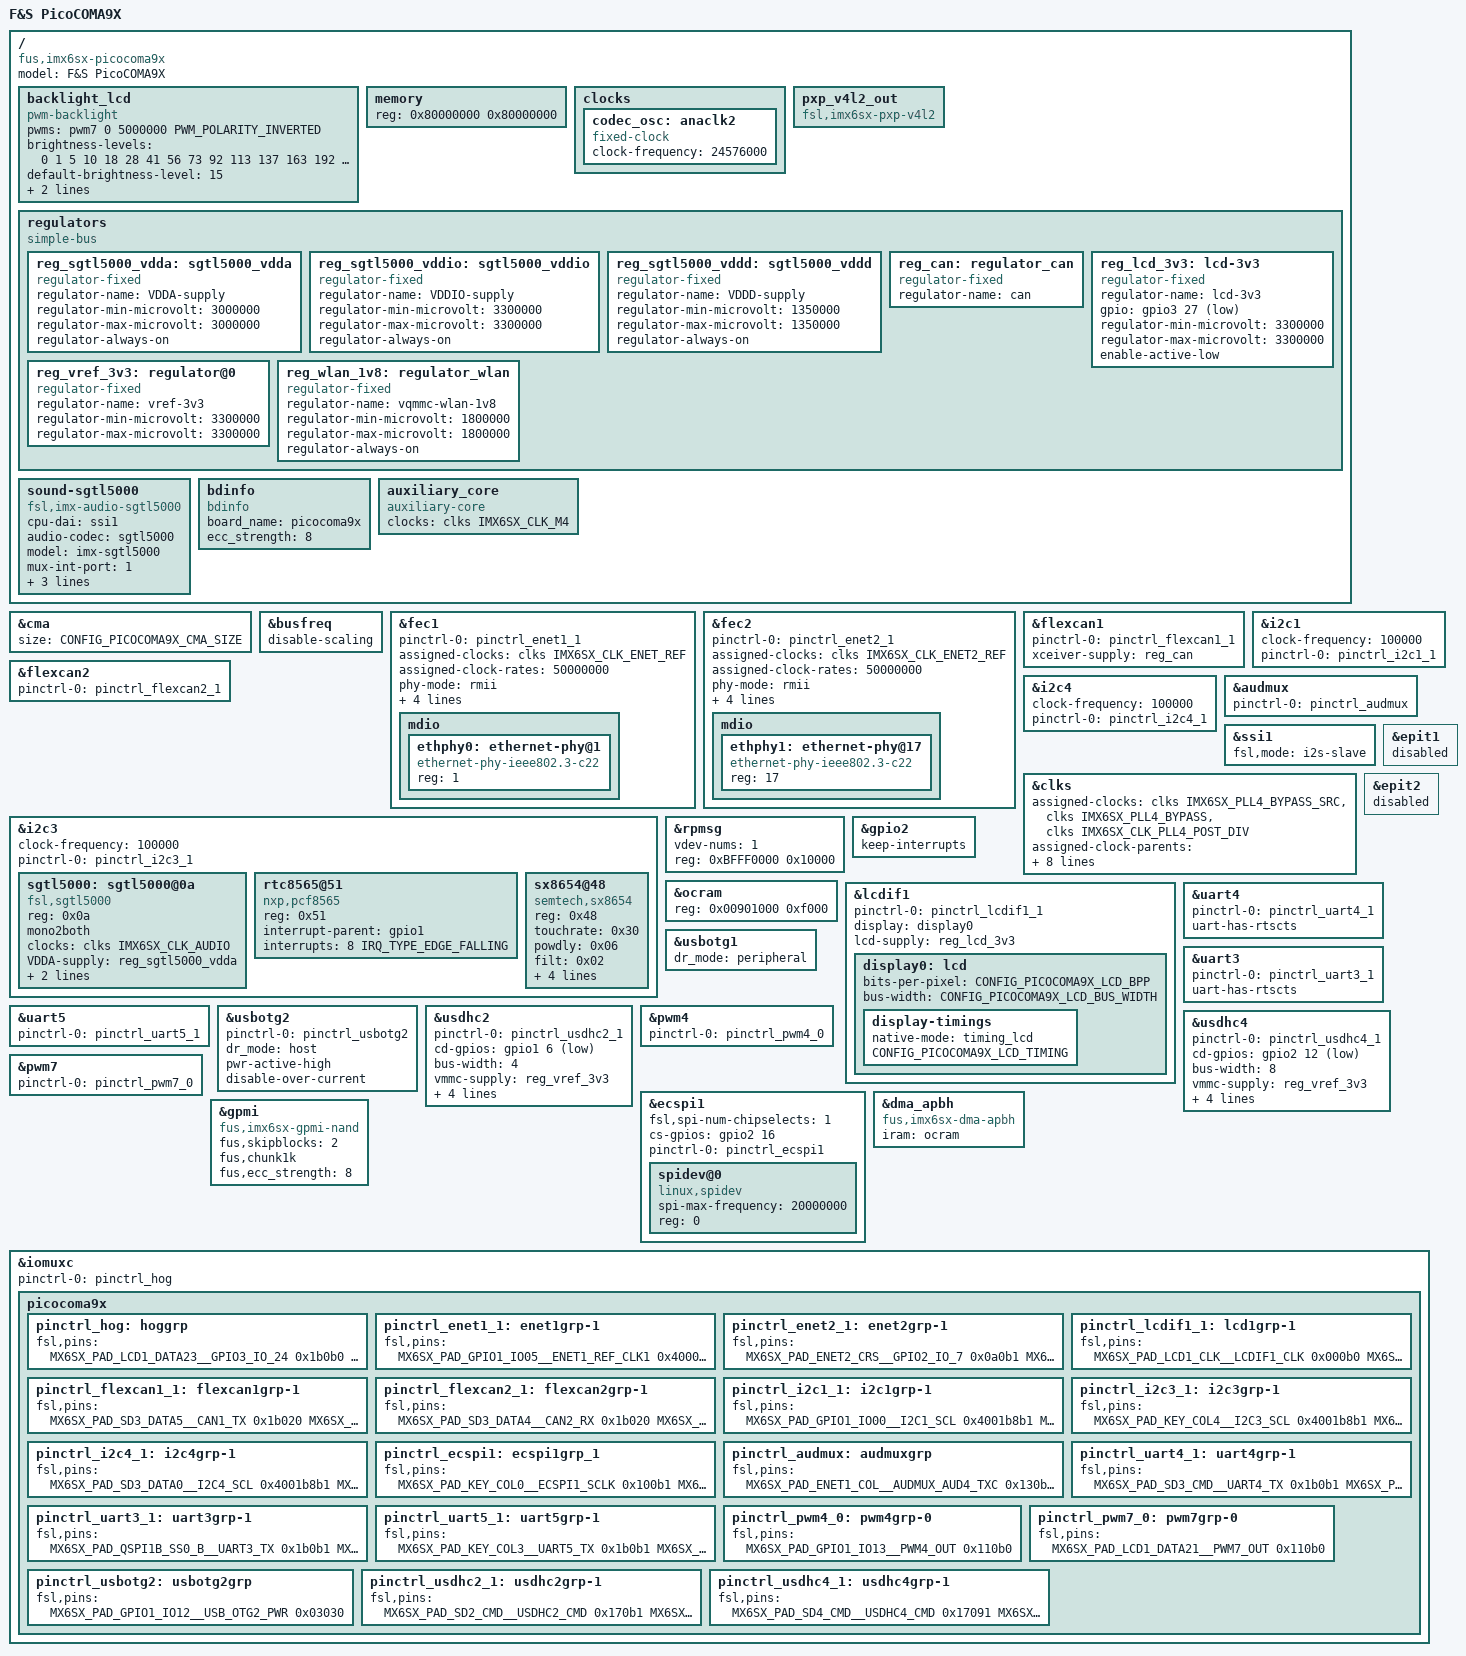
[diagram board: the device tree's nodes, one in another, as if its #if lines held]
/*
 * Copyright (C) 2016-2019 F&S Elektronik Systeme GmbH
 *
 * This program is free software; you can redistribute it and/or modify
 * it under the terms of the GNU General Public License version 2 as
 * published by the Free Software Foundation.
 */

/dts-v1/;

/* Set board revision as 3-digit number, e.g. 110 for board rev. 1.10 */
#define CONFIG_PICOCOMA9X_BOARD_REVISION	111

/* Activate this if you want to use the Cortex-M4 core */
//#define SUPPORT_M4

#define DISPLAY_NONE	0	/* No display on this port */
#define DISPLAY_LCD	1	/* LCD via RGB adapter */

/*
 * Set the display configuration:
 *
 * - If you have no display, set LCDIF0 to DISPLAY_NONE.
 * - If you have a display, set LCDIF0 to DISPLAY_LCD.
 */
#define CONFIG_PICOCOMA9X_LCDIF0	DISPLAY_LCD

/*
 * Configure LCD settings here (ignored if LCD is not used)
 */
#define CONFIG_PICOCOMA9X_LCD /* enable LCD nodes */
#define CONFIG_PICOCOMA9X_LCD_BPP	32
#define CONFIG_PICOCOMA9X_LCD_BUS_WIDTH	18
#define CONFIG_PICOCOMA9X_LCD_TIMING \
lcd_wvga {				\
	clock-frequency = <33500000>;	\
	hactive = <800>;  		\
	vactive = <480>;		\
	hfront-porch = <40>;		\
	hback-porch = <88>;		\
	hsync-len = <128>;		\
	vback-porch = <33>;		\
	vfront-porch = <10>;		\
	vsync-len = <2>;		\
	hsync-active = <0>;		\
	vsync-active = <0>;		\
	de-active = <1>;		\
	pixelclk-active = <1>;		\
}

/*
 * On PicoCOMA9X, you can either use 16 bpp (RGB565) and HSYNC/VSYNC (default)
 * or 18 bpp (RGB666) and DE synchronization. In this case the two additional
 * color signals replace the HSYNC/VSYNC signals. Activate the following line
 * if you want to use 18 bpp and DE.
 */
//#define CONFIG_PICOCOMA9X_LCD_18BPP_DE

/* GPU is only available on CPU variants MCIMX6X3... and MCIMX6X4... */
#define CONFIG_PICOCOMA9X_GPU

/* TOUCH */
#define CONFIG_PICOCOMA9X_4WTOUCH_SX8655_ONBOARD /* SX8655 res. touch */

/* CMA: Set 160 MB for Continuous Memory Allocator */
#define CONFIG_PICOCOMA9X_CMA_SIZE 0x0A000000

/* ETH_A */
#define CONFIG_PICOCOMA9X_ETH_A

/*
 * ETH_B, this is a hardware option. ETH_B replaces the audio signals, so no
 * audio is possible if ETH_B is available. The PicoCOMA9X version with 2x ETH
 * is mainly meant for the PCOMnetA9X.
 */
//#define CONFIG_PICOCOMA9X_ETH_B

/* AUDIO; not available if ETH_B is equipped (see above) */
#define CONFIG_PICOCOMA9X_AUDIO

/*
 * WLAN/BLUETOOTH; the PCOMnet carrier board can be equipped with a WLAN only
 * or a combined WLAN/Bluetooth chip. WLAN is connected via SD-Card pins and
 * Bluetooth via UART_B.
 */
//#define CONFIG_PICOCOMA9X_WLAN
//#define CONFIG_PICOCOMA9X_BLUETOOTH

/* CAN_A on pins 30+31 */
#define CONFIG_PICOCOMA9X_CAN_A

/* CAN_B: You can use a second CAN port on pins 32+33 instead of I2C_A */
//#define CONFIG_PICOCOMA9X_CAN_B

/* I2C_A on pins 32/33 */
#define CONFIG_PICOCOMA9X_I2C_A

/* I2C_B: You can have a second I2C port on pins 30+31 instead of CAN_A */
//#define CONFIG_PICOCOMA9X_I2C_B

/* SPI_A on pins 26-29 */
#define CONFIG_PICOCOMA9X_SPI_A

/* SD_A on pins 34-39, optional CD is on pin 12 */
#define CONFIG_PICOCOMA9X_SD_A
#define CONFIG_PICOCOMA9X_SD_A_CD

/* On-board EMMC */
#define CONFIG_PICOCOMA9X_EMMC

/* USB DEVICE */
#define CONFIG_PICOCOMA9X_USB_DEVICE

/* USB HOST */
#define CONFIG_PICOCOMA9X_USB_HOST

/* UART_A TXD/RXD on pins 17/18, RTS/CTS on pins 69/11 */
#define CONFIG_PICOCOMA9X_UART_A
#define CONFIG_PICOCOMA9X_UART_A_RTSCTS

/* UART_B TXD/RXD on pins 13/14, RTS/CTS on pins 15/16 */
#define CONFIG_PICOCOMA9X_UART_B
#define CONFIG_PICOCOMA9X_UART_B_RTSCTS
//#define CONFIG_PICOCOMA9X_UART_B_RS485

/*
 * UART_C: You can have a third UART port with TXD/RXD on pins 15/16 if RTS/CTS
 * of UART_B are not needed.
 */
//#define CONFIG_PICOCOMA9X_UART_C

/* Check for invalid CONFIG combinations */

/*
 * Exclude devices from Linux that are used by the Cortex-M4 FreeRTOS examples
 *
 * - UART_B used for debug output/UART examples
 * - SPI_A pins used as GPIOs in different examples and in SPI examples
 * - CAN_A used in CAN examples
 * - I2C_A used in I2C examples
 */
#ifdef SUPPORT_M4
#undef CONFIG_PICOCOMA9X_CAN_A
#undef CONFIG_PICOCOMA9X_I2C_A
#undef CONFIG_PICOCOMA9X_UART_B
#undef CONFIG_PICOCOMA9X_SPI_A
#endif

/* If ETH_B is equipped, audio will not work */
#ifdef CONFIG_PICOCOMA9X_ETH_B
#undef CONFIG_PICOCOMA9X_AUDIO
#endif

/* CAN_A takes precedence over I2C_B */
#ifdef CONFIG_PICOCOMA9X_CAN_A
#undef CONFIG_PICOCOMA9X_I2C_B
#endif

/* I2C_A takes precedence over CAN_B */
#ifdef CONFIG_PICOCOMA9X_I2C_A
#undef CONFIG_PICOCOMA9X_CAN_B
#endif

/* If bluetooth is active, UART_B should use RTS/CTS */
#ifdef CONFIG_PICOCOMA9X_BLUETOOTH
#ifndef CONFIG_PICOCOMA9X_UART_B_RTSCTS
#define CONFIG_PICOCOMA9X_UART_B_RTSCTS
#endif
#endif

/* If RTS/CTS on UART_B are both active, setting RS485 is not necessary */
#ifdef CONFIG_PICOCOMA9X_UART_B_RTSCTS
#undef CONFIG_PICOCOMA9X_UART_B_RS485
#endif

/* UART_C is only possible if UART_B has no RTS/CTS */
#if defined(CONFIG_PICOCOMA9X_UART_B_RTSCTS) \
	|| defined(CONFIG_PICOCOMA9X_UART_B_RS485)
#undef CONFIG_PICOCOMA9X_UART_C
#endif

/* If WLAN is available on PCOMnet via SD_A, the CD signal is used as IRQ */
#ifdef CONFIG_PICOCOMA9X_WLAN
#undef CONFIG_PICOCOMA9X_SD_A_CD
#ifndef CONFIG_PICOCOMA9X_SD_A
#define CONFIG_PICOCOMA9X_SD_A
#endif
#endif


#include "imx6sx.dtsi"
#include <dt-bindings/pwm/pwm.h>

/ {
	model = "F&S PicoCOMA9X";
	compatible = "fus,imx6sx-picocoma9x", "fsl,imx6sx";

	backlight_lcd {
		compatible = "pwm-backlight";
		pwms = <&pwm7 0 5000000 PWM_POLARITY_INVERTED>;
		brightness-levels = <0 1 5 10 18 28 41 56
				73 92 113 137 163 192 222 255>;
		default-brightness-level = <15>;
		fb-names = "mxs-lcdif0";
		enable-gpios = <&gpio3 24 GPIO_ACTIVE_LOW>;
	};

	memory {
		reg = <0x80000000 0x80000000>;
	};

	clocks {
		codec_osc: anaclk2 {
			#clock-cells = <0>;
			compatible = "fixed-clock";
			clock-frequency = <24576000>;
		};
	};

	pxp_v4l2_out {
		compatible = "fsl,imx6sx-pxp-v4l2", "fsl,imx6sl-pxp-v4l2";
		status = "okay";
	};

	regulators {
		compatible = "simple-bus";

		/* SGTL5000 analog voltage */
		reg_sgtl5000_vdda: sgtl5000_vdda {
			compatible = "regulator-fixed";
			regulator-name = "VDDA-supply";
			regulator-min-microvolt = <3000000>;
			regulator-max-microvolt = <3000000>;
			regulator-always-on;
		};

		/* SGTL5000 I/O voltage */
		reg_sgtl5000_vddio: sgtl5000_vddio {
			compatible = "regulator-fixed";
			regulator-name = "VDDIO-supply";
			regulator-min-microvolt = <3300000>;
			regulator-max-microvolt = <3300000>;
			regulator-always-on;
		};

		/* SGTL5000 internal digital voltage */
		reg_sgtl5000_vddd: sgtl5000_vddd {
			compatible = "regulator-fixed";
			regulator-name = "VDDD-supply";
			regulator-min-microvolt = <1350000>;
			regulator-max-microvolt = <1350000>;
			regulator-always-on;
		};

		reg_can: regulator_can {
			compatible = "regulator-fixed";
			regulator-name = "can";
		};

		reg_lcd_3v3: lcd-3v3 {
			compatible = "regulator-fixed";
			regulator-name = "lcd-3v3";
			gpio = <&gpio3 27 GPIO_ACTIVE_LOW>;
			regulator-min-microvolt = <3300000>;
			regulator-max-microvolt = <3300000>;
			enable-active-low;
		};

		reg_vref_3v3: regulator@0 {
			compatible = "regulator-fixed";
			regulator-name = "vref-3v3";
			regulator-min-microvolt = <3300000>;
			regulator-max-microvolt = <3300000>;
		};

#ifdef CONFIG_PICOCOMA9X_WLAN
		reg_wlan_1v8: regulator_wlan {
			compatible = "regulator-fixed";
			regulator-name = "vqmmc-wlan-1v8";
			regulator-min-microvolt = <1800000>;
			regulator-max-microvolt = <1800000>;
			regulator-always-on;
		};
#endif

		/* USB_OTG1 only usable in device mode, no regulator needed */

		/* USB_OTG2_PWR done by USB controller, no regulator needed */
#if 0 //###
		reg_usb_otg2_vbus: usb_otg2_vbus {
			compatible = "regulator-fixed";
			regulator-name = "usb_otg2_vbus";
			regulator-min-microvolt = <5000000>;
			regulator-max-microvolt = <5000000>;
			gpio = <&gpio1 12 0>;
			enable-active-high;
		};
#endif //###
	};

#ifdef CONFIG_PICOCOMA9X_AUDIO
	sound-sgtl5000 {
		compatible = "fsl,imx-audio-sgtl5000";
		cpu-dai = <&ssi1>;
		audio-codec = <&sgtl5000>;
		model = "imx-sgtl5000";
		mux-int-port = <1>;  /* SSI1=1, SSI2=2, SSI3=7 */
		mux-ext-port = <4>;
		audio-routing =
//			"MIC_IN", "Mic Jack",
			"Mic Jack", "Mic Bias",
			"LINE_IN", "Line In Jack";
//			"Line Out Jack", "LINE_OUT";
	};
#endif

	/* F&S board information */
	bdinfo {
		compatible = "bdinfo";
		board_name = "picocoma9x";
		ecc_strength = "8";
	};

#ifdef SUPPORT_M4
	/* F&S auxiliary core driver */
	auxiliary_core {
		compatible = "auxiliary-core";
		clocks = <&clks IMX6SX_CLK_M4>;
	};
#endif
};

/* RAM size for Continues Memory Allocator */
&cma {
	size = <CONFIG_PICOCOMA9X_CMA_SIZE>;
};

&busfreq {
	/* Disable bus frequency scaling, because reducing bus frequency to
	   24 MHz does not work with all types of DDR3 RAM */
	disable-scaling;
};

#ifdef CONFIG_PICOCOMA9X_ETH_A
&fec1 {
	pinctrl-names = "default";
	pinctrl-0 = <&pinctrl_enet1_1>;

	assigned-clocks = <&clks IMX6SX_CLK_ENET_REF>;
	assigned-clock-rates = <50000000>;

	phy-mode = "rmii";
	phy-handle = <&ethphy0>;
	phy-supply = <&reg_vref_3v3>;

	fsl,magic-packet;
	fsl,ref-clock-out;

	status = "okay";

	mdio {
		#address-cells = <1>;
		#size-cells = <0>;

		ethphy0: ethernet-phy@1 {
			compatible = "ethernet-phy-ieee802.3-c22";
			reg = <1>;
		};
	};
};
#endif

#ifdef CONFIG_PICOCOMA9X_ETH_B
&fec2 {
	pinctrl-names = "default";
	pinctrl-0 = <&pinctrl_enet2_1>;

	assigned-clocks = <&clks IMX6SX_CLK_ENET2_REF>;
	assigned-clock-rates = <50000000>;

	phy-mode = "rmii";
	phy-handle = <&ethphy1>;
	phy-supply = <&reg_vref_3v3>;

	fsl,magic-packet;
	fsl,ref-clock-out;

	status = "okay";

	mdio {
		#address-cells = <1>;
		#size-cells = <0>;

		ethphy1: ethernet-phy@17 {
			compatible = "ethernet-phy-ieee802.3-c22";
			reg = <17>;
		};
	};
};
#endif

#ifdef CONFIG_PICOCOMA9X_CAN_A
&flexcan1 {
	pinctrl-names = "default";
	pinctrl-0 = <&pinctrl_flexcan1_1>;
	xceiver-supply = <&reg_can>;
	status = "okay";
};
#endif

#ifdef CONFIG_PICOCOMA9X_CAN_B
&flexcan2 {
	pinctrl-names = "default";
	pinctrl-0 = <&pinctrl_flexcan2_1>;
	status = "okay";
};
#endif

#ifdef CONFIG_PICOCOMA9X_I2C_B
&i2c1 {
	clock-frequency = <100000>;
	pinctrl-names = "default";
	pinctrl-0 = <&pinctrl_i2c1_1>;
	status = "okay";
};
#endif

/* I2C3 to RTC, resistive touch controller (SX8655) and SGTL5000 */
&i2c3 {
	clock-frequency = <100000>;
	pinctrl-names = "default";
	pinctrl-0 = <&pinctrl_i2c3_1>;
	status = "okay";

#ifdef CONFIG_PICOCOMA9X_AUDIO
	sgtl5000: sgtl5000@0a {
		compatible = "fsl,sgtl5000";
		reg = <0x0a>;
		mono2both;
		clocks = <&clks IMX6SX_CLK_AUDIO>;
		VDDA-supply = <&reg_sgtl5000_vdda>;
		VDDIO-supply = <&reg_sgtl5000_vddio>;
		VDDD-supply = <&reg_sgtl5000_vddd>;
	};
#endif

	rtc8565@51 {
		compatible = "nxp,pcf8565", "nxp,pcf8563";
		reg = <0x51>;
		interrupt-parent = <&gpio1>;
		interrupts = <8 IRQ_TYPE_EDGE_FALLING>;
	};

	/* Touch driver SX8654 */
#ifdef CONFIG_PICOCOMA9X_4WTOUCH_SX8655_ONBOARD
	sx8654@48 {
		compatible = "semtech,sx8654";
		reg = <0x48>;
		touchrate = <0x30>;
		powdly = <0x06>;
		filt = <0x02>;
		setdly = <0x08>;
		pinctrl-names = "default";
		interrupt-parent = <&gpio1>;
		interrupts = <4 IRQ_TYPE_EDGE_FALLING>;
		reset-gpio = <&gpio1 2 GPIO_ACTIVE_LOW>;
	};
#endif
};

#ifdef CONFIG_PICOCOMA9X_I2C_A
&i2c4 {
	clock-frequency = <100000>;
	pinctrl-names = "default";
	pinctrl-0 = <&pinctrl_i2c4_1>;
	status = "okay";
};
#endif

#ifdef CONFIG_PICOCOMA9X_AUDIO
&audmux {
	pinctrl-names = "default";
	pinctrl-0 = <&pinctrl_audmux>;
	status = "okay";
};

&ssi1 {
	fsl,mode = "i2s-slave";
	status = "okay";
};
#endif

&clks {
	assigned-clocks = <&clks IMX6SX_PLL4_BYPASS_SRC>,
			  <&clks IMX6SX_PLL4_BYPASS>,
			  <&clks IMX6SX_CLK_PLL4_POST_DIV>;
	assigned-clock-parents = <&clks IMX6SX_CLK_LVDS2_IN>,
				 <&clks IMX6SX_PLL4_BYPASS_SRC>;
	assigned-clock-rates = <0>, <0>, <24576000>;
/* Needed for low power mode to tell A9 which clocks might be shared with M4 */
#ifdef SUPPORT_M4
	/* Shared memory in OCRAM, keep clear from Linux */
	fsl,shared-mem-addr = <0x91F000>;
	fsl,shared-mem-size = <0x1000>;
        fsl,shared-clks-number = <0x23>;
        fsl,shared-clks-index = <IMX6SX_CLK_PLL2_BUS
				 IMX6SX_CLK_PLL2_PFD0
                        	 IMX6SX_CLK_PLL2_PFD2
				 IMX6SX_CLK_PLL3_USB_OTG
                        	 IMX6SX_CLK_PLL3_PFD1
				 IMX6SX_CLK_PLL3_PFD2
                        	 IMX6SX_CLK_PLL3_PFD3
				 IMX6SX_CLK_PLL4_AUDIO
                        	 IMX6SX_CLK_PLL5_VIDEO
                        	 IMX6SX_CLK_OCRAM
				 IMX6SX_CLK_CAN1_SERIAL
                        	 IMX6SX_CLK_CAN1_IPG
				 IMX6SX_CLK_CAN2_SERIAL
                        	 IMX6SX_CLK_CAN2_IPG
				 IMX6SX_CLK_CANFD
                        	 IMX6SX_CLK_ECSPI1
				 IMX6SX_CLK_ECSPI2
                        	 IMX6SX_CLK_ECSPI3
				 IMX6SX_CLK_ECSPI4
                        	 IMX6SX_CLK_ECSPI5
				 IMX6SX_CLK_QSPI1
                        	 IMX6SX_CLK_QSPI2
				 IMX6SX_CLK_SSI1
                        	 IMX6SX_CLK_SSI2
				 IMX6SX_CLK_SSI3
                        	 IMX6SX_CLK_UART_SERIAL
				 IMX6SX_CLK_UART_IPG
                        	 IMX6SX_CLK_PERIPH_CLK2_SEL
				 IMX6SX_CLK_DUMMY
                        	 IMX6SX_CLK_I2C1
				 IMX6SX_CLK_I2C2
                        	 IMX6SX_CLK_I2C3
				 IMX6SX_CLK_I2C4
                        	 IMX6SX_CLK_EPIT1
				 IMX6SX_CLK_EPIT2>;
#endif
};

#ifdef SUPPORT_M4
/* epit1 and epit2 are used by Cortex-M4 examples for timing purposes */
&epit1{
        status = "disabled";
};

&epit2{
        status = "disabled";
};

/* rpmsg is used for communication between Cortex-A9 and Cortex-M4 cores */
&rpmsg {
	/*
	 * 64K for one rpmsg instance, default using 2 rpmsg instances:
	 * --0x9FF00000~0x9FF0FFFF: pmic,pm,audio,keys,gpio,sensor
	 * --0x9FF10000~0x9FF1FFFF: pingpong,virtual tty
	 */
	vdev-nums = <1>;
	reg = <0xBFFF0000 0x10000>;
	status = "okay";
};

/* Keep interrupts on GPIO2 if M4 already owns it */
&gpio2 {
        keep-interrupts;
};

/*
 * OCRAM usage (128KB):
 *   0x00900000 - 0x00900FFF: Cortex-A9/Linux: CPU idle + bus frequency code
 *   0x00901000 - 0x0090FFFF: Cortex-A9/Linux: DMA descriptors, GPU
 *   0x00910000 - 0x0091EFFF: Cortex-M4/FreeRTOS: Code/Data
 *   0x0091F000 - 0x0091FFFF: Cortex-A9+M4: Shared memory for shared clocks
 */
&ocram {
        reg = <0x00901000 0xf000>;
};
#endif

#if (CONFIG_PICOCOMA9X_LCDIF0 == DISPLAY_LCD)
&lcdif1 {
	pinctrl-names = "default";
	pinctrl-0 = <&pinctrl_lcdif1_1>;	/* Remove when already active */
	display = <&display0>;			/* Remove when already active */
	lcd-supply = <&reg_lcd_3v3>;
	status = "okay";

	display0: lcd {
		bits-per-pixel = <CONFIG_PICOCOMA9X_LCD_BPP>;
		bus-width = <CONFIG_PICOCOMA9X_LCD_BUS_WIDTH>;
		display-timings {
			native-mode = <&timing_lcd>;
			timing_lcd: CONFIG_PICOCOMA9X_LCD_TIMING;
		};
	};
};
#endif

#ifndef CONFIG_PICOCOMA9X_GPU
&gpu {
	status = "disabled";
};
#endif

/* UART_A */
#ifdef CONFIG_PICOCOMA9X_UART_A
&uart4 {
	/* UART_A: TXD, RXD,  U$1 CON-10Pol on PCOMnet SKIT, default tty */
	pinctrl-names = "default";
	pinctrl-0 = <&pinctrl_uart4_1>;
#ifdef CONFIG_PICOCOMA9X_UART_A_RTSCTS
	uart-has-rtscts;
#endif
	status = "okay";
};
#endif

/* UART_B */
#ifdef CONFIG_PICOCOMA9X_UART_B
&uart3 {
	pinctrl-names = "default";
	pinctrl-0 = <&pinctrl_uart3_1>;
#if defined(CONFIG_PICOCOMA9X_UART_B_RTSCTS) \
	|| defined(CONFIG_PICOCOMA9X_UART_B_RS485)
	uart-has-rtscts;
#endif
	status = "okay";
};
#endif

/* UART_C */
#ifdef CONFIG_PICOCOMA9X_UART_C
&uart5 {
	/* UART_C: TXD, RXD, */
	pinctrl-names = "default";
	pinctrl-0 = <&pinctrl_uart5_1>;
	status = "okay";
};
#endif

/* USB device */
#ifdef CONFIG_PICOCOMA9X_USB_DEVICE
&usbotg1 {
	dr_mode = "peripheral";
	status = "okay";
};
#endif

/* USB host */
#ifdef CONFIG_PICOCOMA9X_USB_HOST
&usbotg2 {
	pinctrl-names = "default";
	pinctrl-0 = <&pinctrl_usbotg2>;
//###	vbus-supply = <&reg_usb_otg2_vbus>;
	dr_mode = "host";
	pwr-active-high;
	disable-over-current;
	status = "okay";
};
#endif

/* SD Card */
#ifdef CONFIG_PICOCOMA9X_SD_A
&usdhc2 {
	/* External normal-sized SD slot on efus SKIT */
	pinctrl-names = "default";
	pinctrl-0 = <&pinctrl_usdhc2_1>;
#ifdef CONFIG_PICOCOMA9X_SD_A_CD
	cd-gpios = <&gpio1 6 GPIO_ACTIVE_LOW>;
#else
	non-removable;
#endif
	bus-width = <4>;
	vmmc-supply = <&reg_vref_3v3>;	/* VDD */
#ifdef CONFIG_PICOCOMA9X_WLAN
	vqmmc-supply = <&reg_wlan_1v8>;	/* VDD_IO */
	voltage-ranges = <1800 1800>;
	enable-sdio-wakeup;
#else
	vqmmc-supply = <&reg_vref_3v3>;	/* VDD_IO */
	voltage-ranges = <3300 3300>;
	no-1-8-v;
#endif
	keep-power-in-suspend;
	status = "okay";
};
#endif

/* EMMC */
#ifdef CONFIG_PICOCOMA9X_EMMC
&usdhc4 {
	pinctrl-names = "default";
	pinctrl-0 = <&pinctrl_usdhc4_1>;
	/* eMMC is non-removable, but CD tells us if it is equipped or not */
	cd-gpios = <&gpio2 12 GPIO_ACTIVE_LOW>;
	//non-removable;
	bus-width = <8>;
	vmmc-supply = <&reg_vref_3v3>;	/* VDD */
	vqmmc-supply = <&reg_vref_3v3>;	/* VDD_IO */
	voltage-ranges = <3300 3300>;
	no-1-8-v;
	keep-power-in-suspend;
	status = "okay";
};
#endif

/* PWM4 - available if second phy is not assembled*/
#ifndef CONFIG_PICOCOMA9X_ETH_B
&pwm4 {
	pinctrl-names = "default";
	pinctrl-0 = <&pinctrl_pwm4_0>;
	status = "okay";
};
#endif

/* PWM7 used for backlight brightness */
&pwm7 {
	pinctrl-names = "default";
	pinctrl-0 = <&pinctrl_pwm7_0>;
	#pwm-cells = <3>;
	status = "okay";
};


/*
 * SPI_A is ECSPI1. Please note: in board revisions 1.00 and 1.1x, SPI_A_MOSI
 * (pin 27) and SPI_A_CS0 (29) are swapped, be careful
 */
#ifdef CONFIG_PICOCOMA9X_SPI_A
&ecspi1 {
	fsl,spi-num-chipselects = <1>;
	cs-gpios = <&gpio2 16 0>;
	pinctrl-names = "default";
	pinctrl-0 = <&pinctrl_ecspi1>;
	status = "okay";

	spidev@0 {
		#address-cells = <1>;
		#size-cells = <1>;
		compatible = "linux,spidev";
		spi-max-frequency = <20000000>;
		reg = <0>;
	};
};
#endif

&dma_apbh {
	/* Switch to F&S implementation of APBH DMA driver for GPMI (NAND) */
	compatible = "fus,imx6sx-dma-apbh", "fus,imx28-dma-apbh";
	iram = <&ocram>;
};

&gpmi {
	/* Switch to F&S implementation of GPMI NAND driver */
	compatible = "fus,imx6sx-gpmi-nand";
	pinctrl-names = "default";
	fus,skipblocks = <2>;
	fus,chunk1k;
	fus,ecc_strength = <8>;		/* Spare area 64 bytes */
//###	fus,ecc_strength = <52>;	/* Spare area 224 bytes */
	status = "okay";
};

&iomuxc {
	pinctrl-names = "default";
	pinctrl-0 = <&pinctrl_hog>;

 	picocoma9x {
		pinctrl_hog: hoggrp {
			fsl,pins = <

				/* VBL_ON active low */
				MX6SX_PAD_LCD1_DATA23__GPIO3_IO_24	0x1b0b0

				/* VLCD_ON active low */
				MX6SX_PAD_LCD1_RESET__GPIO3_IO_27	0x130b1

				/* LCD_DEN, gpio for display standby */
				MX6SX_PAD_LCD1_DATA22__GPIO3_IO_23	0x130b1

				/* BootGPIO */
				MX6SX_PAD_GPIO1_IO09__GPIO1_IO_9	0x1b0b1

#if (CONFIG_PICOCOMA9X_BOARD_REVISION < 110)
				/* TOUCH INTERUPT*/
				MX6SX_PAD_GPIO1_IO03__GPIO1_IO_3	0x1b0b0
				/* RTC IRQ */
				MX6SX_PAD_GPIO1_IO04__GPIO1_IO_4	0x1b0b0
#else
				/* TOUCH INTERUPT*/
				MX6SX_PAD_GPIO1_IO04__GPIO1_IO_4	0x1b0b0
				/* RTC IRQ */
				MX6SX_PAD_GPIO1_IO08__GPIO1_IO_8	0x1b0b0
#endif
				/* Reset for external touches on I2C3 */
				MX6SX_PAD_GPIO1_IO02__GPIO1_IO_2	0x1b0b0
#if (CONFIG_PICOCOMA9X_BOARD_REVISION >= 110)
				/* DVS */
				MX6SX_PAD_QSPI1B_DQS__GPIO4_IO_28	0x1b0b1
#endif
			>;
		};

#ifdef CONFIG_PICOCOMA9X_ETH_A
		pinctrl_enet1_1: enet1grp-1 {
			fsl,pins = <
				/* GPIO to reset phy, activated in uboot */
//				MX6SX_PAD_ENET2_CRS__GPIO2_IO_7		0x0a0b1
				/* 50MHz base clock from CPU to PHY */
				MX6SX_PAD_GPIO1_IO05__ENET1_REF_CLK1	0x400000a1
				/* MDIO */
				MX6SX_PAD_ENET1_MDC__ENET1_MDC		0x0a0b1
				MX6SX_PAD_ENET1_MDIO__ENET1_MDIO	0x0a0b1
				/* FEC1 */
				MX6SX_PAD_RGMII1_TD0__ENET1_TX_DATA_0	0x0a0b1
				MX6SX_PAD_RGMII1_TD1__ENET1_TX_DATA_1	0x0a0b1
				MX6SX_PAD_RGMII1_TX_CTL__ENET1_TX_EN	0x0a0b1
				MX6SX_PAD_RGMII1_RXC__ENET1_RX_ER	0x03081
				MX6SX_PAD_RGMII1_RD0__ENET1_RX_DATA_0	0x03081
				MX6SX_PAD_RGMII1_RD1__ENET1_RX_DATA_1	0x03081
				MX6SX_PAD_RGMII1_RX_CTL__ENET1_RX_EN	0x03081
			>;
		};
#endif

#ifdef CONFIG_PICOCOMA9X_ETH_B
		pinctrl_enet2_1: enet2grp-1 {
			fsl,pins = <
				/* gpio to reset phy, activated in uboot */
				MX6SX_PAD_ENET2_CRS__GPIO2_IO_7		0x0a0b1
				/* 50MHz base clock from CPU to PHY */
				MX6SX_PAD_ENET2_TX_CLK__ENET2_REF_CLK2	0x400000a1
				/* MDIO */
				MX6SX_PAD_ENET1_COL__ENET2_MDC		0x0a0b1
				MX6SX_PAD_ENET1_CRS__ENET2_MDIO		0x0a0b1
				/* fec2 */
				MX6SX_PAD_RGMII2_TD0__ENET2_TX_DATA_0	0x0a0b1
				MX6SX_PAD_RGMII2_TD1__ENET2_TX_DATA_1	0x0a0b1
				MX6SX_PAD_RGMII2_TX_CTL__ENET2_TX_EN	0x0a0b1
				MX6SX_PAD_RGMII2_RD0__ENET2_RX_DATA_0	0x03081
				MX6SX_PAD_RGMII2_RD1__ENET2_RX_DATA_1	0x03081
				MX6SX_PAD_RGMII2_RXC__ENET2_RX_ER	0x03081
				MX6SX_PAD_RGMII2_RX_CTL__ENET2_RX_EN	0x03081
			>;
		};
#endif

#ifdef CONFIG_PICOCOMA9X_LCD
		pinctrl_lcdif1_1: lcd1grp-1 {
			fsl,pins = <
				MX6SX_PAD_LCD1_CLK__LCDIF1_CLK		0x000b0
				MX6SX_PAD_LCD1_DATA01__LCDIF1_DATA_1	0x000b0
				MX6SX_PAD_LCD1_DATA02__LCDIF1_DATA_2	0x000b0
				MX6SX_PAD_LCD1_DATA03__LCDIF1_DATA_3	0x000b0
				MX6SX_PAD_LCD1_DATA04__LCDIF1_DATA_4	0x000b0
				MX6SX_PAD_LCD1_DATA05__LCDIF1_DATA_5	0x000b0
				MX6SX_PAD_LCD1_DATA06__LCDIF1_DATA_6	0x000b0
				MX6SX_PAD_LCD1_DATA07__LCDIF1_DATA_7	0x000b0
				MX6SX_PAD_LCD1_DATA08__LCDIF1_DATA_8	0x000b0
				MX6SX_PAD_LCD1_DATA09__LCDIF1_DATA_9	0x000b0
				MX6SX_PAD_LCD1_DATA10__LCDIF1_DATA_10	0x000b0
				MX6SX_PAD_LCD1_DATA11__LCDIF1_DATA_11	0x000b0
				MX6SX_PAD_LCD1_DATA13__LCDIF1_DATA_13	0x000b0
				MX6SX_PAD_LCD1_DATA14__LCDIF1_DATA_14	0x000b0
				MX6SX_PAD_LCD1_DATA15__LCDIF1_DATA_15	0x000b0
				MX6SX_PAD_LCD1_DATA16__LCDIF1_DATA_16	0x000b0
				MX6SX_PAD_LCD1_DATA17__LCDIF1_DATA_17	0x000b0
				MX6SX_PAD_LCD1_ENABLE__LCDIF1_ENABLE	0x000b0
#ifdef CONFIG_PICOCOMA9X_LCD_18BPP_DE
				MX6SX_PAD_LCD1_DATA00__LCDIF1_DATA_0	0x000b0
				MX6SX_PAD_LCD1_DATA12__LCDIF1_DATA_12	0x000b0
#else
				MX6SX_PAD_LCD1_HSYNC__LCDIF1_HSYNC	0x000b0
				MX6SX_PAD_LCD1_VSYNC__LCDIF1_VSYNC	0x000b0
#endif
			>;
		};
#endif

#ifdef CONFIG_PICOCOMA9X_CAN_A
		pinctrl_flexcan1_1: flexcan1grp-1 {
			fsl,pins = <
				MX6SX_PAD_SD3_DATA5__CAN1_TX		0x1b020
				MX6SX_PAD_SD3_DATA7__CAN1_RX		0x1b020
			>;
		};
#endif

#ifdef CONFIG_PICOCOMA9X_CAN_B
		pinctrl_flexcan2_1: flexcan2grp-1 {
			fsl,pins = <
				MX6SX_PAD_SD3_DATA4__CAN2_RX		0x1b020
				MX6SX_PAD_SD3_DATA6__CAN2_TX		0x1b020
			>;
		};
#endif

#ifdef CONFIG_PICOCOMA9X_I2C_B
		pinctrl_i2c1_1: i2c1grp-1 {
			fsl,pins = <
				MX6SX_PAD_GPIO1_IO00__I2C1_SCL		0x4001b8b1
				MX6SX_PAD_GPIO1_IO01__I2C1_SDA		0x4001b8b1
			>;
		};
#endif

		pinctrl_i2c3_1: i2c3grp-1 {
			fsl,pins = <
				MX6SX_PAD_KEY_COL4__I2C3_SCL		0x4001b8b1
				MX6SX_PAD_KEY_ROW4__I2C3_SDA		0x4001b8b1
			>;
		};

#ifdef CONFIG_PICOCOMA9X_I2C_A
		pinctrl_i2c4_1: i2c4grp-1 {
			fsl,pins = <
				MX6SX_PAD_SD3_DATA0__I2C4_SCL		0x4001b8b1
				MX6SX_PAD_SD3_DATA1__I2C4_SDA		0x4001b8b1
			>;
		};
#endif

#ifdef CONFIG_PICOCOMA9X_SPI_A
		pinctrl_ecspi1: ecspi1grp_1 {
			fsl,pins = <
				MX6SX_PAD_KEY_COL0__ECSPI1_SCLK		0x100b1
				MX6SX_PAD_KEY_COL1__ECSPI1_MISO		0x100b1
				MX6SX_PAD_KEY_ROW0__ECSPI1_MOSI		0x100b1
				MX6SX_PAD_KEY_ROW1__GPIO2_IO_16		0x100b1
			>;
		};
#endif

#ifdef CONFIG_PICOCOMA9X_AUDIO
		pinctrl_audmux: audmuxgrp {
			fsl,pins = <
				MX6SX_PAD_ENET1_COL__AUDMUX_AUD4_TXC	0x130b0
				MX6SX_PAD_ENET1_CRS__AUDMUX_AUD4_TXD	0x130b0
				MX6SX_PAD_ENET1_TX_CLK__AUDMUX_AUD4_RXD	0x110b0
				MX6SX_PAD_ENET1_RX_CLK__AUDMUX_AUD4_TXFS 0x130b0
				MX6SX_PAD_GPIO1_IO07__AUDMUX_MCLK	0x130b0
			>;
		};
#endif

#ifdef CONFIG_PICOCOMA9X_UART_A
		pinctrl_uart4_1: uart4grp-1 {
			fsl,pins = <
				MX6SX_PAD_SD3_CMD__UART4_TX		0x1b0b1
				MX6SX_PAD_SD3_DATA3__UART4_RX		0x1b0b1
				MX6SX_PAD_SD3_CLK__UART4_RTS_B		0x1b0b1
				MX6SX_PAD_SD3_DATA2__UART4_CTS_B	0x1b0b1
			>;
		};
#endif

#ifdef CONFIG_PICOCOMA9X_UART_B
		pinctrl_uart3_1: uart3grp-1 {
			fsl,pins = <
				MX6SX_PAD_QSPI1B_SS0_B__UART3_TX	0x1b0b1
				MX6SX_PAD_QSPI1B_SCLK__UART3_RX		0x1b0b1

#ifdef CONFIG_PICOCOMA9X_UART_B_RTSCTS
				MX6SX_PAD_QSPI1B_DATA1__UART3_RTS_B	0x1b0b1
#endif
#if defined(CONFIG_PICOCOMA9X_UART_B_RTSCTS) \
	|| defined(CONFIG_PICOCOMA9X_UART_B_RS485)
				MX6SX_PAD_QSPI1B_DATA0__UART3_CTS_B	0x1b0b1
#endif
			>;
		};
#endif

#ifdef CONFIG_PICOCOMA9X_UART_C
		pinctrl_uart5_1: uart5grp-1 {
			fsl,pins = <
				MX6SX_PAD_KEY_COL3__UART5_TX		0x1b0b1
				MX6SX_PAD_KEY_ROW3__UART5_RX		0x1b0b1
			>;
		};
#endif

#ifndef CONFIG_PICOCOMA9X_ETH_B
		pinctrl_pwm4_0: pwm4grp-0 {
			fsl,pins = <
				MX6SX_PAD_GPIO1_IO13__PWM4_OUT		0x110b0
			>;
		};
#endif

		/* Backlight Control */
		pinctrl_pwm7_0: pwm7grp-0 {
			fsl,pins = <
				MX6SX_PAD_LCD1_DATA21__PWM7_OUT		0x110b0
			>;
		};

#ifdef CONFIG_PICOCOMA9X_USB_HOST
		pinctrl_usbotg2: usbotg2grp {
			fsl,pins = <
				/* USB_OTG2_PWR, active high */
//###				MX6SX_PAD_GPIO1_IO12__GPIO1_IO_12	0x03030
				MX6SX_PAD_GPIO1_IO12__USB_OTG2_PWR	0x03030
			>;
		};
#endif

#ifdef CONFIG_PICOCOMA9X_SD_A
		/* SD card (may be WLAN on PCOMnet carrier board) */
		pinctrl_usdhc2_1: usdhc2grp-1 {
			fsl,pins = <
				MX6SX_PAD_SD2_CMD__USDHC2_CMD		0x170b1
				MX6SX_PAD_SD2_CLK__USDHC2_CLK		0x100b1
				MX6SX_PAD_SD2_DATA0__USDHC2_DATA0	0x170b1
				MX6SX_PAD_SD2_DATA1__USDHC2_DATA1	0x170b1
				MX6SX_PAD_SD2_DATA2__USDHC2_DATA2	0x170b1
				MX6SX_PAD_SD2_DATA3__USDHC2_DATA3	0x170b1
#ifdef CONFIG_PICOCOMA9X_SD_A_CD
				/* Card Detect (CD), active low (pull-up) */
				MX6SX_PAD_GPIO1_IO06__GPIO1_IO_6	0x17000
#endif
#ifdef CONFIG_PICOCOMA9X_WLAN
				/* WLAN IRQ, active low */
				MX6SX_PAD_GPIO1_IO06__GPIO1_IO_6	0x17000
#endif
			>;
		};
#endif

#ifdef CONFIG_PICOCOMA9X_EMMC
		/* EMMC */
		pinctrl_usdhc4_1: usdhc4grp-1 {
			fsl,pins = <
				MX6SX_PAD_SD4_CMD__USDHC4_CMD		0x17091
				MX6SX_PAD_SD4_CLK__USDHC4_CLK		0x10091
				MX6SX_PAD_SD4_RESET_B__USDHC4_RESET_B	0x10091
				MX6SX_PAD_SD4_DATA0__USDHC4_DATA0	0x17091
				MX6SX_PAD_SD4_DATA1__USDHC4_DATA1	0x17091
				MX6SX_PAD_SD4_DATA2__USDHC4_DATA2	0x17091
				MX6SX_PAD_SD4_DATA3__USDHC4_DATA3	0x17091
				MX6SX_PAD_SD4_DATA4__USDHC4_DATA4	0x17091
				MX6SX_PAD_SD4_DATA5__USDHC4_DATA5	0x17091
				MX6SX_PAD_SD4_DATA6__USDHC4_DATA6	0x17091
				MX6SX_PAD_SD4_DATA7__USDHC4_DATA7	0x17091
				/* Card Detect (CD) */
				MX6SX_PAD_KEY_COL2__GPIO2_IO_12		0x17000
			>;
		};
#endif
	};
};
